# kmac: IP-XACT component
VLNV tenstorrent.com:ocah:kmac:1.0

## Address spaces and blocks
kmac_mmap.kmac: base 'h0, range 'h1000, width 32

## Registers
Registers are 32-bit, write-only, reset 0x0 unless marked. A register's access mark holds for its fields unless they carry their own. Offsets are from the block's base; lines under a group give offsets from that group; [hi:lo] are bit positions; {n}, {i} and the like mark numbered series; 'fields as' and 'values as' point back to an identical list; <NAME> marks a mode.

## kmac_mmap.kmac — Accelerator for Keccak-based keyed hash message authentication code and SHA-3 hash functions; with SCA and FI countermeasures
Base 0x00000000
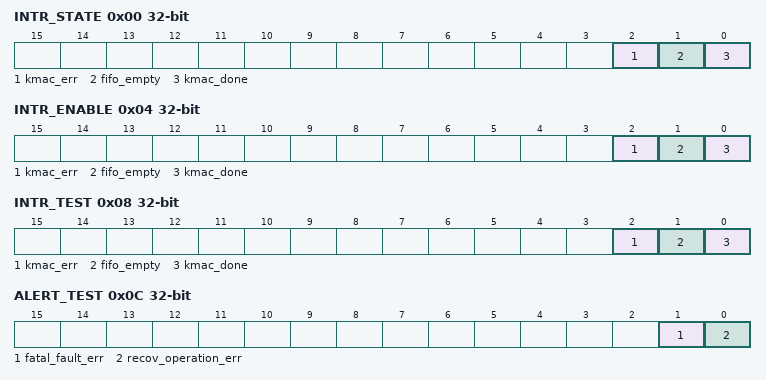
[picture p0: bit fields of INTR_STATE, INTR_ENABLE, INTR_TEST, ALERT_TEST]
0x00 INTR_STATE access per field
  [2] kmac_err rw write-1-clears — KMAC/SHA3 error occurred. ERR_CODE register shows the details
  [1] fifo_empty ro — The message FIFO is empty. This interrupt is raised only if the message FIFO is actually writable by software, i.e., if all of the following conditions are met: i) The KMAC block is not exercised by a hardware application interface. ii) The SHA3 block is in the Absorb state. iii) Software has not yet written the Process command to finish the absorption process. For the interrupt to be raised, the message FIFO must also have been full previously. Otherwise, the hardware empties the FIFO faster than software can fill it and there is no point in interrupting the software to inform it about the message FIFO being empty.
  [0] kmac_done rw write-1-clears — KMAC/SHA3 absorbing has been completed
0x04 INTR_ENABLE rw
  [2] kmac_err — Enable interrupt when !!INTR_STATE.kmac_err is set.
  [1] fifo_empty — Enable interrupt when !!INTR_STATE.fifo_empty is set.
  [0] kmac_done — Enable interrupt when !!INTR_STATE.kmac_done is set.
0x08 INTR_TEST
  [2] kmac_err — Write 1 to force !!INTR_STATE.kmac_err to 1.
  [1] fifo_empty — Write 1 to force !!INTR_STATE.fifo_empty to 1.
  [0] kmac_done — Write 1 to force !!INTR_STATE.kmac_done to 1.
0x0C ALERT_TEST
  [1] fatal_fault_err — Write 1 to trigger one alert event of this kind.
  [0] recov_operation_err — Write 1 to trigger one alert event of this kind.
0x10 CFG_REGWEN ro reset 0x1
  [0] en — Configuration enable.
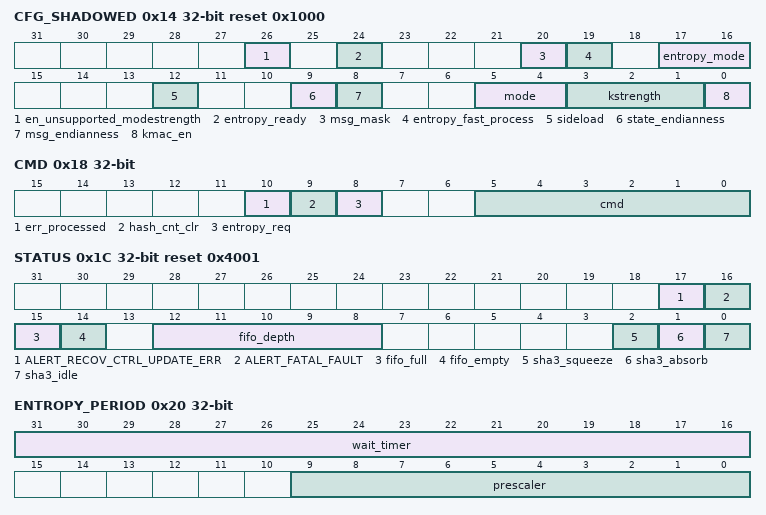
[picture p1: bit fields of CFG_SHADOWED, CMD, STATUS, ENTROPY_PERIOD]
0x14 CFG_SHADOWED rw reset 0x1000
  [26] en_unsupported_modestrength — Enable Unsupported Mode and Strength configs. SW may set this field for KMAC to move forward with unsupported Keccak Mode and Strength configurations, such as cSHAKE512. If not set, KMAC won't propagate the SW command (CmdStart) to the rest of the blocks (AppIntf, KMAC Core, SHA3).
  [24] entropy_ready — Entropy Ready status. Software sets this field to allow the entropy generator in KMAC to fetch the entropy and run.
  [20] msg_mask — Message Masking with PRNG. If 1, KMAC applies PRNG to the input messages to the Keccak module when KMAC mode is on.
  [19] entropy_fast_process — Entropy Fast process mode. If 1, entropy logic uses garbage data while not processing the KMAC key block. It will re-use previous entropy value and will not expand the entropy when it is consumed. Only it refreshes the entropy while processing the secret key block. This process should not be used if SCA resistance is required because it may cause side channel leakage.
  [17:16] entropy_mode — Entropy Mode Using this field, software can configure mode of operation of the internal pseudo-random number generator (PRNG). Note that once software has configured a value different from `idle_mode` after reset, and set the !!CFG_SHADOWED.entropy_ready bit afterwards, the PRNG configuration cannot be changed anymore (unless an EDN request timeout occurs when running in EDN mode). Further writes to this field will change the value received upon reading the register, but they will be ignored by the internal hardware.
  [12] sideload — Sideloaded Key. Deprecated: defaults to 1 (sideload). Set to 0 for DV testing with SW key path only. If 1, KMAC uses KeyMgr sideloaded key for SW initiated KMAC operation. KMAC uses the sideloaded key regardless of this configuration when KeyMgr initiates the KMAC operation for Key Derivation Function (KDF).
  [9] state_endianness — State Endianness. If 1 then each individual word in the !!STATE output register is converted to big-endian byte order. The order of the words in relation to one another is not changed. This setting does not affect how the state is interpreted during computation.
  [8] msg_endianness — Message Endianness. If 1 then each individual multi-byte value, regardless of its alignment, written to !!MSG_FIFO will be added to the message in big-endian byte order. If 0, each value will be added to the message in little-endian byte order. A message written to !!MSG_FIFO one byte at a time will not be affected by this setting. From a hardware perspective byte swaps are performed on a TL-UL word granularity.
  [5:4] mode — Keccak hashing mode. This module supports SHA3 main hashing algorithm and the part of its derived functions, SHAKE and cSHAKE with limitations. This field is to select the mode.
  [3:1] kstrength — Hashing Strength 3 bit field to select the security strength of SHA3 hashing engine. If mode field is set to SHAKE or cSHAKE, only 128 and 256 strength can be selected. Other value will result error when hashing starts.
  [0] kmac_en — KMAC datapath enable. If this bit is 1, the KMAC mode is active and the secret key is prepended to the incoming message.
0x18 CMD reset not defined
  [10] err_processed write-1-clears — When error occurs and one of the state machine stays at Error handling state, SW may process the error based on ERR_CODE, then let FSM back to the reset state
  [9] hash_cnt_clr write-1-clears — Software can set this bit to 1 to manually clear !!ENTROPY_REFRESH_HASH_CNT.
  [8] entropy_req write-1-clears — Software can set this bit to 1 to manually trigger the reseeding of the internal PRNG when running in EDN mode. This will also clear !!ENTROPY_REFRESH_HASH_CNT. Note that the hardware may miss the trigger pulse if the module is not idle, or if the module is currently performing a reseed operation.
  [5:0] cmd write-1-clears — Issue a command to the KMAC/SHA3 IP. The command is sparse encoded. To prevent sw from writing multiple commands at once, the field is defined as enum.
0x1C STATUS ro reset 0x4001 (reset mask 0x34001)
  [17] ALERT_RECOV_CTRL_UPDATE_ERR — An update error has not occurred (0) or has occurred (1) in the shadowed Control Register. KMAC operation needs to be restarted by re-writing the Control Register.
  [16] ALERT_FATAL_FAULT — No fatal fault has occurred inside the KMAC unit (0). A fatal fault has occurred and the KMAC unit needs to be reset (1), Examples for such faults include i) TL-UL bus integrity fault ii) storage errors in the shadow registers iii) errors in the message, round, or key counter iv) any internal FSM entering an invalid state v) an error in the redundant lfsr
  [15] fifo_full — Message FIFO Full indicator
  [14] fifo_empty — Message FIFO Empty indicator. The FIFO's `Pass` parameter is set to `1'b 1`. So, by default, if the SHA engine is ready, the write data to FIFO just passes through. In this case, `fifo_depth` remains **0**. `fifo_empty`, however, lowers the value to **0** for a cycle, then goes back to the empty state, **1**. See the "Message FIFO" section in the spec for the reason.
  [12:8] fifo_depth — Count of occupied entries in the message FIFO.
  [2] sha3_squeeze — If 1, SHA3 completes sponge absorbing stage. In this stage, SW can manually run the hashing engine.
  [1] sha3_absorb — If 1, SHA3 is receiving message stream and processing it
  [0] sha3_idle — If 1, SHA3 hashing engine is in idle state.
0x20 ENTROPY_PERIOD rw
  [31:16] wait_timer — EDN request wait timer. The entropy module in KMAC waits up to this field in the timer pulse after it sends request to EDN module. If the timer expires, the entropy module moves to an error state and notifies to the system. If there is a pending EDN request during wait timer update, then this update is delayed until the EDN request is complete. If 0, the entropy module waits the EDN response always. If EDN does not respond in this configuration, the software shall reset the IP.
  [9:0] prescaler — EDN Wait timer prescaler. EDN Wait timer has 16 bit value. The timer value is increased when the timer pulse is generated. Timer pulse is raises when the number of the clock cycles hit this prescaler value. The exact period of the timer pulse is unknown as the KMAC input clock may contain jitters.
0x24 ENTROPY_REFRESH_HASH_CNT ro
  [9:0] hash_cnt — Hash (KMAC) counter
0x28 ENTROPY_REFRESH_THRESHOLD_SHADOWED rw
  [9:0] threshold — Hash Threshold
0x2C ENTROPY_SEED reset not defined
  [31:0] seed — 32-bit chunk of the entropy generator seed
{0x30+4i} KEY_SHARE0[{i}] (i=0..15) reset not defined
  [31:0] key_0 — 32-bit chunk of up-to 512-bit Secret Key
{0x70+4i} KEY_SHARE1[{i}] (i=0..15) reset not defined
  [31:0] key_0 — 32-bit chunk of up-to 512-bit Secret Key
0xB0 KEY_LEN
  [2:0] len — Key length choice
{0xB4+4i} PREFIX[{i}] (i=0..10) rw
  [31:0] prefix_0 — 32-bit chunk of Encoded NS Prefix
0xE0 ERR_CODE ro
  [31:0] err_code — If the `kmac_err` interrupt occurs, this register has information on the error cause. Bits 31:24 contain the error code (please refer to `err_code_e` in `hw/ip/kmac/rtl/kmac_pkg.sv`) for the encoding, and bits 23:0 contain additional debug information. This register does *not* get cleared when the `kmac_err` interrupt state gets cleared.

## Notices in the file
SPDX-License-Identifier: Apache-2.0
SPDX-FileCopyrightText: 2026 Tenstorrent USA, Inc.
